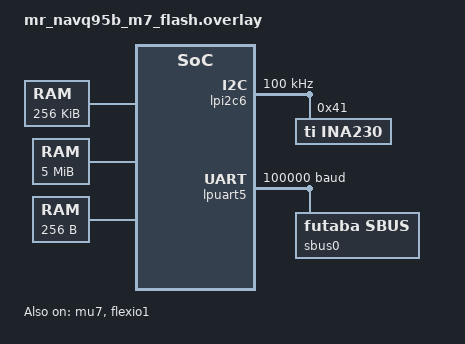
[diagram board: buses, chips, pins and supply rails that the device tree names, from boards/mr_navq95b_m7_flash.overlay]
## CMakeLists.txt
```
#-------------------------------------------------------------------------------
# Zephyr Cerebri Application
#
# Copyright (c) 2023 CogniPilot Foundation
# SPDX-License-Identifier: Apache-2.0

cmake_minimum_required(VERSION 3.13.1)

find_package(Zephyr REQUIRED HINTS $ENV{ZEPHYR_BASE})

project(rdd2 LANGUAGES C)

# Suppress strncpy warning from upstream Zephyr USB MSC code (usbd_msc_scsi.c)
# The strncpy usage is correct for fixed-size SCSI fields that don't need null termination
zephyr_compile_options(-Wno-stringop-truncation)

set(CYECCA_PYTHON ${CMAKE_CURRENT_SOURCE_DIR}/../../scripts/cyecca_python)

set(CYECCA_PATH $ENV{ZEPHYR_BASE}/../modules/lib/cyecca)

set(flags
  -std=c11
  -Wall
  -Wextra
  -Werror
  -Wstrict-prototypes
  -Waggregate-return
  -Wbad-function-cast
  -Wcast-align
  -Wcast-qual
  -Wfloat-equal
  -Wformat-security
  -Wlogical-op
  -Wmissing-declarations
  # ubxlib includes geographiclib which dir doesn't exist
  #-Wmissing-include-dirs
  -Wmissing-prototypes
  -Wnested-externs
  -Wpointer-arith
  -Wredundant-decls
  -Wsequence-point
  -Wshadow
  -Wstrict-prototypes
  -Wswitch
  -Wundef
  -Wunreachable-code
  -Wunused-but-set-parameter
  -Wwrite-strings
  )
string(JOIN " " flags ${flags})

set(SOURCE_FILES
  src/boot_banner.c
  src/input_mapping.c
  )

if (CONFIG_CEREBRI_RDD2_FSM)
  list(APPEND SOURCE_FILES src/fsm.c)
endif()

if (CONFIG_CEREBRI_RDD2_ESTIMATE)
  list(APPEND SOURCE_FILES src/estimate.c)
endif()

if (CONFIG_CEREBRI_RDD2_ALLOCATION)
  list(APPEND SOURCE_FILES src/allocation.c)
endif()

if (CONFIG_CEREBRI_RDD2_LIGHTING)
  list(APPEND SOURCE_FILES src/lighting.c)
endif()

if (CONFIG_CEREBRI_RDD2_COMMAND)
  list(APPEND SOURCE_FILES
    src/command.c
    src/mode_bezier.c
    src/mode_velocity.c
    src/mode_attitude.c
    src/mode_attitude_rate.c)
endif()

if (CONFIG_CEREBRI_RDD2_POSITION)
  list(APPEND SOURCE_FILES
    src/position.c)
elseif (CONFIG_CEREBRI_RDD2_LOGLINEAR_POSITION)
  list(APPEND SOURCE_FILES
    src/log_linear_position.c)
endif()

if (CONFIG_CEREBRI_RDD2_ANGULAR_VELOCITY)
  list(APPEND SOURCE_FILES
    src/angular_velocity.c)
endif()

if (CONFIG_CEREBRI_RDD2_ATTITUDE)
  list(APPEND SOURCE_FILES
    src/attitude.c)
elseif (CONFIG_CEREBRI_RDD2_LOGLINEAR_ATTITUDE)
  list(APPEND SOURCE_FILES
    src/log_linear_attitude.c)
endif()

set(CASADI_DEST_DIR ${CMAKE_BINARY_DIR}/app/rdd2/casadi)

set(CASADI_FILES
  ${CASADI_DEST_DIR}/rdd2.c
  ${CASADI_DEST_DIR}/rdd2_loglinear.c
  ${CASADI_DEST_DIR}/bezier.c
  )

if (CONFIG_CEREBRI_RDD2_CASADI)
  list(APPEND SOURCE_FILES ${CASADI_FILES})
endif()

add_custom_command(OUTPUT ${CASADI_DEST_DIR}/rdd2.c
  COMMAND ${CYECCA_PYTHON} ${CYECCA_PATH}/cyecca/models/rdd2.py ${CASADI_DEST_DIR}
  DEPENDS ${CYECCA_PATH}/cyecca/models/rdd2.py)

add_custom_command(OUTPUT ${CASADI_DEST_DIR}/rdd2_loglinear.c
  COMMAND ${CYECCA_PYTHON} ${CYECCA_PATH}/cyecca/models/rdd2_loglinear.py ${CASADI_DEST_DIR}
  DEPENDS ${CYECCA_PATH}/cyecca/models/rdd2_loglinear.py)

add_custom_command(OUTPUT ${CASADI_DEST_DIR}/bezier.c
  COMMAND ${CYECCA_PYTHON} ${CYECCA_PATH}/cyecca/models/bezier.py ${CASADI_DEST_DIR}
  DEPENDS ${CYECCA_PATH}/cyecca/models/bezier.py)

set_source_files_properties(
  ${SOURCE_FILES}
  PROPERTIES COMPILE_FLAGS
  "${flags}"
  )

set_source_files_properties(
  ${CASADI_FILES}
  PROPERTIES COMPILE_FLAGS
  "${flags}\
  -Wno-unused-parameter\
  -Wno-missing-prototypes\
  -Wno-missing-declarations\
  -Wno-float-equal")

target_sources(app PRIVATE ${SOURCE_FILES})

target_include_directories(app SYSTEM BEFORE PRIVATE
  ${ZEPHYR_BASE}/include
  ${CMAKE_BINARY_DIR}
  )

if(CONFIG_BOARD STREQUAL "vmu_rt1170")
  zephyr_linker_sources(ITCM_SECTION boards/vmu_rt1170_itcm_linker.ld)
  zephyr_code_relocate(LIBRARY nanopb LOCATION ITCM_TEXT)
endif()

if(CONFIG_BOARD STREQUAL "mr_vmu_tropic")
  zephyr_linker_sources(ITCM_SECTION boards/mr_vmu_tropic_itcm_linker.ld)
  zephyr_code_relocate(LIBRARY nanopb LOCATION ITCM_TEXT)
endif()

if(CONFIG_BOARD STREQUAL "mr_navq95a" OR CONFIG_BOARD STREQUAL "mr_navq95b")
  # Relocate code to ITCM
  zephyr_linker_sources(ITCM_SECTION boards/mr_navq95a_itcm_linker.ld)
  zephyr_code_relocate(LIBRARY nanopb LOCATION ITCM_TEXT)
  # Relocate log ring buffer to SDRAM
  zephyr_linker_sources(SECTIONS boards/navq95.ld)
  # Relocate data to OCRAM since zephyr doesn't have an auto spillover
  zephyr_code_relocate(FILES ${SOURCE_FILES} LOCATION OCRAM_DATA)
  zephyr_code_relocate(FILES ${SOURCE_FILES} LOCATION OCRAM_BSS)
  zephyr_code_relocate(FILES ${SOURCE_FILES} LOCATION OCRAM_NOINIT)
  zephyr_code_relocate(LIBRARY cerebri_synapse_topic LOCATION OCRAM_BSS)
  zephyr_code_relocate(LIBRARY cerebri_synapse_topic LOCATION OCRAM_NOINIT)
endif()

# vi: ts=2 sw=2 et
```

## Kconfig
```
# Copyright (c) 2023, CogniPilot Foundation
# SPDX-License-Identifier: Apache-2.0

mainmenu "CogniPilot - Cerebri - RDD2"
menu "Zephyr"
source "Kconfig.zephyr"
endmenu

menu "RDD2"
config CEREBRI_RDD2_ESTIMATE
  bool "enable estimate"
  depends on CEREBRI_RDD2_CASADI
  help
    Enable estimator

config CEREBRI_RDD2_FSM
  bool "enable finite state machine"
  help
    Enable fintie state machine

config CEREBRI_RDD2_LIGHTING
  bool "enable lighting"
  help
    Enable lighting

config CEREBRI_RDD2_COMMAND
  bool "enable command"
  depends on CEREBRI_RDD2_ALLOCATION
  help
    Enable joy

config CEREBRI_RDD2_ALLOCATION
  bool "enable mixing"
  help
    Enable mixing

config CEREBRI_RDD2_POSITION
  bool "enable position"
  depends on CEREBRI_RDD2_CASADI
  help
    Enable position

config CEREBRI_RDD2_ANGULAR_VELOCITY
  bool "enable velocity"
  depends on CEREBRI_RDD2_ALLOCATION
  depends on CEREBRI_RDD2_CASADI
  help
    Enable velocity

config CEREBRI_RDD2_ATTITUDE
  bool "enable attitude"
  depends on CEREBRI_RDD2_ANGULAR_VELOCITY
  depends on CEREBRI_RDD2_CASADI
  help
    Enable attitude

config CEREBRI_RDD2_CASADI
  bool "enable casadi code"
  help
    Enable Casadi generated code

config CEREBRI_RDD2_ESTIMATE_ODOMETRY_ETHERNET
  bool "fuse odometry from ethernet"
  depends on CEREBRI_RDD2_ESTIMATE
  help
    Enable odometry from ethernet

config CEREBRI_RDD2_BATTERY_NCELLS
  int "number of cells in battery"
  default 4
  help
    Number of cells in battery

config CEREBRI_RDD2_BATTERY_CELL_MIN_MILLIVOLT
  int "millivolts per cell before shutdown"
  default 3300
  help
    millivolts per cell before shutdown

config CEREBRI_RDD2_BATTERY_CELL_LOW_MILLIVOLT
  int "millivolts per cell before warning"
  default 3500
  help
    millivolts per cell before warning

config CEREBRI_RDD2_BATTERY_CELL_NOM_MILLIVOLT
  int "nominal millivolts per cell"
  default 3700
  help
    nominal millivolts per cell

config CEREBRI_RDD2_BATTERY_CELL_MAX_MILLIVOLT
  int "max millivolts per cell before warning"
  default 4300
  help
    max millivolts per cell before warning

config CEREBRI_RDD2_GAIN_HEADING
  int "heading gain"
  default 100
  help
    Steering = Heading error * GAIN_/ 1000

config CEREBRI_RDD2_GAIN_CROSS_TRACK
  int "cross track gain"
  default 100
  help
    Steering = Cross track error * GAIN / 1000

config CEREBRI_RDD2_GAIN_ALONG_TRACK
  int "along track gain"
  default 100
  help
    Steering = Along track error * GAIN / 1000

config CEREBRI_RDD2_MAX_VELOCITY_MM_S
  int "max velocity, mm/s"
  default 1000
  help
    Max velocity in mm/s

config CEREBRI_RDD2_MOTOR_L_MM
  int "moment arm for props"
  default 174
  help
    moment arm for props

config CEREBRI_RDD2_MOTOR_CM
  int "motor moment coefficient * 1e6"
  default 16000
  help
    moment arm for props

config CEREBRI_RDD2_MOTOR_CT
  int "motor thrust coefficient * 1e9"
  default 8549
  help
    moment thrust coefficient * 1e9

config CEREBRI_RDD2_POS_KP
  int "pos kp * 1e6"
  default 2000000
  help
    pos kp * 1e6

config CEREBRI_RDD2_VEL_KP
  int "vel kp * 1e6"
  default 2000000
  help
    vel kp * 1e6

config CEREBRI_RDD2_X_KI
  int "x ki * 1e6"
  default 100000
  help
    x ki * 1e6

config CEREBRI_RDD2_Y_KI
  int "y ki * 1e6"
  default 100000
  help
    y ki * 1e6

config CEREBRI_RDD2_Z_KI
  int "z ki * 1e6"
  default 100000
  help
    z ki * 1e6

config CEREBRI_RDD2_X_IMAX
  int "x imax * 1e6"
  default 250000
  help
    x ki * 1e6

config CEREBRI_RDD2_Y_IMAX
  int "y imax * 1e6"
  default 250000
  help
    y ki * 1e6

config CEREBRI_RDD2_Z_IMAX
  int "z imax * 1e6"
  default 250000
  help
    z imax * 1e6

config CEREBRI_RDD2_ROLL_KP
  int "roll kp * 1e6"
  default 2000000
  help
    roll kp * 1e6

config CEREBRI_RDD2_PITCH_KP
  int "pitch kp * 1e6"
  default 2000000
  help
    pitch kp * 1e6

config CEREBRI_RDD2_YAW_KP
  int "yaw kp * 1e6"
  default 1000000
  help
    yaw kp * 1e6

config CEREBRI_RDD2_ROLLRATE_KP
  int "rollrate kp * 1e6"
  default 300000
  help
    rollrate kp * 1e6

config CEREBRI_RDD2_PITCHRATE_KP
  int "pitchrate kp * 1e6"
  default 300000
  help
    pitchrate kp * 1e6

config CEREBRI_RDD2_YAWRATE_KP
  int "yawrate kp * 1e6"
  default 300000
  help
    yawrate kp * 1e6

config CEREBRI_RDD2_ROLLRATE_KI
  int "rollrate ki * 1e6"
  default 50000
  help
    rollrate ki * 1e6

config CEREBRI_RDD2_PITCHRATE_KI
  int "pitchrate ki * 1e6"
  default 50000
  help
    pitchrate ki * 1e6

config CEREBRI_RDD2_YAWRATE_KI
  int "yawrate ki * 1e6"
  default 50000
  help
    yawrate ki * 1e6

config CEREBRI_RDD2_ROLLRATE_KD
  int "rollrate kd * 1e6"
  default 0
  help
    rollrate kd * 1e6

config CEREBRI_RDD2_PITCHRATE_KD
  int "pitchrate kd * 1e6"
  default 0
  help
    pitchrate kd * 1e6

config CEREBRI_RDD2_YAWRATE_KD
  int "yawrate kd * 1e6"
  default 0
  help
    yawrate kd * 1e6

config CEREBRI_RDD2_ATTITUDE_RATE_FCUT
  int "fcut [hz] * 1e3"
  default 20000
  help
    attitude_rate cut frequency * 1e3

config CEREBRI_RDD2_ROLLRATE_IMAX
  int "rollrate imax * 1e3"
  default 20000
  help
    rollrate imax * 1e6

config CEREBRI_RDD2_PITCHRATE_IMAX
  int "pitchate imax * 1e3"
  default 20000
  help
    pitchrate imax * 1e6

config CEREBRI_RDD2_YAWRATE_IMAX
  int "yawrate imax * 1e6"
  default 20000
  help
    yawrate imax * 1e6

config CEREBRI_RDD2_THRUST_TRIM
  int "thrust_trim * 1e3 [N}"
  default 21952
  help
    thrust trim * 1e3 [N]

config CEREBRI_RDD2_THRUST_DELTA
  int "thrust delta* 1e3 [N}"
  default 19756
  help
    thrust delta imax * 1e3 [N}

config CEREBRI_RDD2_LOG_LINEAR_ATTITUDE
  bool "enable loglinear attitude control"
  help
    Enable loglinear atitude control

config CEREBRI_RDD2_LOG_LINEAR_POSITION
  bool "enable loglinear position control"
  help
    Enable loglinear atitude position

config CEREBRI_RDD2_ATTITUDE_EST_ACCEL_GAIN
  int "attitude rate accel gain"
  default 40
  help
    attitude rate accel gain

config CEREBRI_RDD2_ATTITUDE_EST_MAG_GAIN
  int "attitude rate mag gain"
  default 40
  help
    attitude rate mag gain


module = CEREBRI_RDD2
module-str = cerebri_rdd2
source "subsys/logging/Kconfig.template.log_config"
endmenu
```

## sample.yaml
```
sample:
  description: RDD2
  name: RDD2
common:
  build_only: true
tests:
  rdd2.posix:
    tags:
      - rdd2
    integration_platforms:
      - native_sim
  rdd2.vmu_rt1170/mimxrt1176/cm7:
    tags:
      - rdd2
    integration_platforms:
      - vmu_rt1170/mimxrt1176/cm7
  rdd2.mr_vmu_tropic/mimxrt1064:
    tags:
      - rdd2
    integration_platforms:
      - mr_vmu_tropic/mimxrt1064
  rdd2.mr_navq95a/mimx9596/m7/flash:
    tags:
      - rdd2
    integration_platforms:
      - mr_navq95a/mimx9596/m7/flash
  rdd2.mr_navq95b/mimx9596/m7/flash:
    tags:
      - rdd2
    integration_platforms:
      - mr_navq95b/mimx9596/m7/flash
```

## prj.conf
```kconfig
CONFIG_CEREBRI_APP_NAME="rdd2"

CONFIG_SYS_CLOCK_TICKS_PER_SEC=100000
CONFIG_TICKLESS_KERNEL=n

CONFIG_CEREBRI_DREAM_SIL=n

CONFIG_CEREBRI_RDD2_ESTIMATE=y
CONFIG_CEREBRI_RDD2_FSM=y
CONFIG_CEREBRI_RDD2_COMMAND=y
CONFIG_CEREBRI_RDD2_ALLOCATION=y
CONFIG_CEREBRI_RDD2_POSITION=y
CONFIG_CEREBRI_RDD2_ANGULAR_VELOCITY=y
CONFIG_CEREBRI_RDD2_ATTITUDE=y
CONFIG_CEREBRI_RDD2_LOG_LINEAR_POSITION=y
CONFIG_CEREBRI_RDD2_LOG_LINEAR_ATTITUDE=y
CONFIG_CEREBRI_RDD2_LIGHTING=n
CONFIG_CEREBRI_RDD2_CASADI=y
CONFIG_CEREBRI_ACTUATE_LED_ARRAY_COUNT=36

CONFIG_CEREBRI_ACTUATE_LED_ARRAY=y
CONFIG_CEREBRI_ACTUATE_SOUND=n

CONFIG_NET_BUF_RX_COUNT=24
CONFIG_NET_PKT_RX_COUNT=24

CONFIG_CEREBRI_SENSE_RC=y
CONFIG_INPUT_MODE_SYNCHRONOUS=y
CONFIG_CEREBRI_SENSE_POWER=y
CONFIG_CEREBRI_SENSE_SAFETY=n
CONFIG_ZROS_SENSE_IMU=n
CONFIG_ZROS_SENSE_MAG=n

CONFIG_CEREBRI_RDD2_ESTIMATE_ODOMETRY_ETHERNET=n
CONFIG_CEREBRI_SYNAPSE_ETH_RX=y
CONFIG_CEREBRI_SYNAPSE_ETH_TX=y
CONFIG_CEREBRI_SYNAPSE_LOG_SDCARD=y

CONFIG_CEREBRI_SYNAPSE_TOPIC=y
CONFIG_CEREBRI_CORE_COMMON=y
CONFIG_CEREBRI_CORE_COMMON_BOOT_BANNER=n
CONFIG_ZROS=y
CONFIG_SHELL_STACK_SIZE=8192
CONFIG_INIT_STACKS=y

CONFIG_LOG=y
CONFIG_LOG_CMDS=y
CONFIG_LOG_MODE_DEFERRED=y
CONFIG_CEREBRI_RDD2_LOG_LEVEL_DBG=n

CONFIG_SPI_RTIO=y
CONFIG_SPI_ASYNC=n
CONFIG_SPI_NXP_LPSPI_DMA=n
CONFIG_ICM4268X_DECODER=y
CONFIG_ICM4268X_STREAM=y

CONFIG_FILE_SYSTEM=y
CONFIG_FAT_FILESYSTEM_ELM=y
CONFIG_DISK_ACCESS=y
CONFIG_FS_FATFS_EXFAT=y
CONFIG_POSIX_FILE_SYSTEM=y
CONFIG_DISK_DRIVER_SDMMC=y
CONFIG_FS_FATFS_MOUNT_MKFS=y

CONFIG_CBPRINTF_FP_SUPPORT=y

# modules
CONFIG_SYNAPSE_PB=y
CONFIG_NANOPB=y

# General config
CONFIG_POSIX_API=y
CONFIG_NEWLIB_LIBC=y
CONFIG_MAIN_THREAD_PRIORITY=5
CONFIG_SYSTEM_WORKQUEUE_PRIORITY=-2

# Networking config
CONFIG_NET_SHELL=y
CONFIG_NETWORKING=y
CONFIG_NET_IPV4=y
CONFIG_NET_IPV6=n
CONFIG_NET_TCP=y
CONFIG_NET_SOCKETS=y

# Network address config
CONFIG_NET_CONFIG_SETTINGS=y
CONFIG_NET_CONFIG_INIT_TIMEOUT=0
CONFIG_NET_STATISTICS=y
CONFIG_NET_MGMT_EVENT_INFO=y
CONFIG_NET_MGMT_EVENT_MONITOR=y
CONFIG_NET_BUF_POOL_USAGE=y
CONFIG_NET_DEBUG_NET_PKT_ALLOC=y
CONFIG_NET_CONFIG_NEED_IPV4=y
CONFIG_NET_CONFIG_MY_IPV4_ADDR="192.0.2.1"
CONFIG_NET_CONFIG_PEER_IPV4_ADDR="192.0.2.2"

# STATS
CONFIG_THREAD_RUNTIME_STATS=y
CONFIG_SCHED_THREAD_USAGE=y
CONFIG_SCHED_THREAD_USAGE_ANALYSIS=y
CONFIG_SCHED_THREAD_USAGE_ALL=y
CONFIG_SCHED_THREAD_USAGE_AUTO_ENABLE=y
```

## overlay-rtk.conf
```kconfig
CONFIG_ZROS_SENSE_RTCM3_SUB=y
CONFIG_GNSS_U_BLOX_F9P_RTK=y
```

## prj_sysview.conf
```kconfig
CONFIG_TRACING=y
CONFIG_THREAD_NAME=y
CONFIG_THREAD_STACK_INFO=y
CONFIG_THREAD_MONITOR=y
CONFIG_SEGGER_SYSTEMVIEW=y
CONFIG_IDLE_STACK_SIZE=2048
CONFIG_SEGGER_SYSTEMVIEW_BOOT_ENABLE=n
CONFIG_SEGGER_SYSVIEW_POST_MORTEM_MODE=n
```

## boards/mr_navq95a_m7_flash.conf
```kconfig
CONFIG_ENTROPY_GENERATOR=y
CONFIG_TEST_RANDOM_GENERATOR=y
CONFIG_SPEED_OPTIMIZATIONS=n
CONFIG_SIZE_OPTIMIZATIONS=n
CONFIG_DEBUG_OPTIMIZATIONS=y
CONFIG_CODE_DATA_RELOCATION=y

CONFIG_TEST=y
CONFIG_UBSAN=n
CONFIG_ASSERT=y
CONFIG_ASSERT_LEVEL=2
CONFIG_ASSERT_VERBOSE=y
CONFIG_CODE_DATA_RELOCATION=y

CONFIG_CMSIS_DSP=y
CONFIG_CMSIS_DSP_FILTERING=y


CONFIG_SYSTEM_WORKQUEUE_STACK_SIZE=4096

CONFIG_STACK_CANARIES=y

CONFIG_ISR_STACK_SIZE=2048
CONFIG_SHELL_STACK_SIZE=4096

CONFIG_LOG_MODE_DEFERRED=y
CONFIG_LOG_MODE_IMMEDIATE=n

CONFIG_FPU=y

# gains
CONFIG_CEREBRI_RDD2_THRUST_TRIM=10976
CONFIG_CEREBRI_RDD2_THRUST_DELTA=10976

CONFIG_CEREBRI_RDD2_ROLL_KP=5000000
CONFIG_CEREBRI_RDD2_PITCH_KP=5000000
CONFIG_CEREBRI_RDD2_YAW_KP=2000000

CONFIG_CEREBRI_RDD2_ROLLRATE_KP=300000
CONFIG_CEREBRI_RDD2_PITCHRATE_KP=300000
CONFIG_CEREBRI_RDD2_YAWRATE_KP=50000

CONFIG_CEREBRI_RDD2_ROLLRATE_KI=50000
CONFIG_CEREBRI_RDD2_PITCHRATE_KI=50000
CONFIG_CEREBRI_RDD2_YAWRATE_KI=50000

CONFIG_CEREBRI_RDD2_ROLLRATE_IMAX=20000
CONFIG_CEREBRI_RDD2_PITCHRATE_IMAX=20000
CONFIG_CEREBRI_RDD2_YAWRATE_IMAX=20000

CONFIG_CEREBRI_RDD2_ROLLRATE_KD=10000
CONFIG_CEREBRI_RDD2_PITCHRATE_KD=10000
CONFIG_CEREBRI_RDD2_YAWRATE_KD=0
CONFIG_CEREBRI_RDD2_ATTITUDE_RATE_FCUT=10000

CONFIG_CEREBRI_RDD2_ATTITUDE_EST_ACCEL_GAIN=140
CONFIG_CEREBRI_RDD2_ATTITUDE_EST_MAG_GAIN=800

# RDD2 APPS
CONFIG_CEREBRI_RDD2_ALLOCATION=y
CONFIG_CEREBRI_RDD2_ANGULAR_VELOCITY=y
CONFIG_CEREBRI_RDD2_ATTITUDE=y
CONFIG_CEREBRI_RDD2_COMMAND=y
CONFIG_CEREBRI_RDD2_ESTIMATE=y
CONFIG_CEREBRI_RDD2_ESTIMATE_ODOMETRY_ETHERNET=n
CONFIG_CEREBRI_RDD2_FSM=y
CONFIG_CEREBRI_RDD2_LIGHTING=n
CONFIG_CEREBRI_RDD2_POSITION=y

# disabled for first live flight
CONFIG_CEREBRI_ACTUATE_PWM_SHELL=n
CONFIG_CEREBRI_ACTUATE_SOUND=n

# config
CONFIG_INPUT=y
CONFIG_INPUT_SBUS=y
CONFIG_INPUT_SBUS_THREAD_STACK_SIZE=1024
CONFIG_INPUT_EVENT_DUMP=n
CONFIG_INPUT_SHELL=n
CONFIG_INPUT_SBUS_REPORT_FILTER=0
CONFIG_INPUT_THREAD_STACK_SIZE=2048

CONFIG_DISK_ACCESS=n
CONFIG_FS_FATFS_EXFAT=n
CONFIG_DISK_DRIVER_SDMMC=n
CONFIG_FS_FATFS_MOUNT_MKFS=n
CONFIG_CEREBRI_SYNAPSE_LOG_SDCARD=y
CONFIG_RING_BUFFER_LARGE=y
CONFIG_ZROS_SENSE_IMU=y

CONFIG_CEREBRI_SENSE_RC=y
#CONFIG_ZROS_SENSE_MAG=y
CONFIG_CEREBRI_SENSE_SAFETY=n

# I3C tends to lock up the system, needs a driver fix
CONFIG_ZROS_SENSE_MAG=n
CONFIG_I3C=n
CONFIG_BMM350=n
CONFIG_BMP581=n

CONFIG_CEREBRI_SYNAPSE_ETH_RX=y
CONFIG_CEREBRI_SYNAPSE_ETH_TX=y
CONFIG_CEREBRI_ACTUATE_LED_ARRAY=n
CONFIG_CEREBRI_SENSE_POWER=y

CONFIG_PWM=y

CONFIG_LED_STRIP=n
CONFIG_APA102_STRIP=n

CONFIG_CAN=y
CONFIG_CAN_MAX_FILTER=5
CONFIG_CAN_SHELL=y

CONFIG_NET_DRIVERS=y

CONFIG_NET_SOCKETS_CAN=y
CONFIG_NET_DEFAULT_IF_CANBUS_RAW=y

CONFIG_CAN_LOG_LEVEL_DBG=n
CONFIG_CAN_FD_MODE=y
CONFIG_SHELL_ARGC_MAX=72
CONFIG_I2C=y
CONFIG_SENSOR=y
CONFIG_SENSOR_SHELL=y
CONFIG_HEAP_MEM_POOL_SIZE=16384

# Debugging
CONFIG_DEBUG_THREAD_INFO=y

# Logging
#CONFIG_LOG_BACKEND_NET=n
#CONFIG_LOG_BACKEND_NET_SERVER="192.0.2.2"

# RPMsg
CONFIG_IPM=y
CONFIG_IPM_MBOX=y
CONFIG_MBOX_NXP_IMX_MU=y
CONFIG_MBOX_INIT_PRIORITY=0
CONFIG_OPENAMP=y
CONFIG_OPENAMP_COPY_RSC_TABLE=y
CONFIG_OPENAMP_RSC_TABLE_NUM_RPMSG_BUFF=8
CONFIG_OPENAMP_RSC_TABLE=y
CONFIG_OPENAMP_MASTER=n
CONFIG_OPENAMP_WITH_DCACHE=y
CONFIG_CEREBRI_SYNAPSE_RPMSG=y

# TTY over RPMsg (uncomment block below to enable)
#CONFIG_SHELL_BACKEND_RPMSG=y
#CONFIG_SHELL_BACKEND_SERIAL=n
#CONFIG_ASSERT=n

# Disable fat and enable rpmsgfs
CONFIG_FILE_SYSTEM_RPMSGFS=y
CONFIG_FAT_FILESYSTEM_ELM=n
CONFIG_FILE_SYSTEM_SHELL=y

# Disable atomic 64 support otherwise open-amp cannot be linked
CONFIG_COMPILER_OPT="-DNO_ATOMIC_64_SUPPORT"
```

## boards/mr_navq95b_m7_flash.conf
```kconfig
CONFIG_ENTROPY_GENERATOR=y
CONFIG_TEST_RANDOM_GENERATOR=y
CONFIG_SPEED_OPTIMIZATIONS=n
CONFIG_SIZE_OPTIMIZATIONS=n
CONFIG_DEBUG_OPTIMIZATIONS=y
CONFIG_CODE_DATA_RELOCATION=y

CONFIG_TEST=y
CONFIG_UBSAN=n
CONFIG_ASSERT=y
CONFIG_ASSERT_LEVEL=2
CONFIG_ASSERT_VERBOSE=y
CONFIG_CODE_DATA_RELOCATION=y

CONFIG_CMSIS_DSP=y
CONFIG_CMSIS_DSP_FILTERING=y


CONFIG_SYSTEM_WORKQUEUE_STACK_SIZE=4096

CONFIG_STACK_CANARIES=y

CONFIG_ISR_STACK_SIZE=2048
CONFIG_SHELL_STACK_SIZE=4096

CONFIG_LOG_MODE_DEFERRED=y
CONFIG_LOG_MODE_IMMEDIATE=n

CONFIG_FPU=y

# gains
CONFIG_CEREBRI_RDD2_THRUST_TRIM=10976
CONFIG_CEREBRI_RDD2_THRUST_DELTA=10976

CONFIG_CEREBRI_RDD2_ROLL_KP=5000000
CONFIG_CEREBRI_RDD2_PITCH_KP=5000000
CONFIG_CEREBRI_RDD2_YAW_KP=2000000

CONFIG_CEREBRI_RDD2_ROLLRATE_KP=300000
CONFIG_CEREBRI_RDD2_PITCHRATE_KP=300000
CONFIG_CEREBRI_RDD2_YAWRATE_KP=50000

CONFIG_CEREBRI_RDD2_ROLLRATE_KI=50000
CONFIG_CEREBRI_RDD2_PITCHRATE_KI=50000
CONFIG_CEREBRI_RDD2_YAWRATE_KI=50000

CONFIG_CEREBRI_RDD2_ROLLRATE_IMAX=20000
CONFIG_CEREBRI_RDD2_PITCHRATE_IMAX=20000
CONFIG_CEREBRI_RDD2_YAWRATE_IMAX=20000

CONFIG_CEREBRI_RDD2_ROLLRATE_KD=10000
CONFIG_CEREBRI_RDD2_PITCHRATE_KD=10000
CONFIG_CEREBRI_RDD2_YAWRATE_KD=0
CONFIG_CEREBRI_RDD2_ATTITUDE_RATE_FCUT=10000

CONFIG_CEREBRI_RDD2_ATTITUDE_EST_ACCEL_GAIN=140
CONFIG_CEREBRI_RDD2_ATTITUDE_EST_MAG_GAIN=800

# RDD2 APPS
CONFIG_CEREBRI_RDD2_ALLOCATION=y
CONFIG_CEREBRI_RDD2_ANGULAR_VELOCITY=y
CONFIG_CEREBRI_RDD2_ATTITUDE=y
CONFIG_CEREBRI_RDD2_COMMAND=y
CONFIG_CEREBRI_RDD2_ESTIMATE=y
CONFIG_CEREBRI_RDD2_ESTIMATE_ODOMETRY_ETHERNET=n
CONFIG_CEREBRI_RDD2_FSM=y
CONFIG_CEREBRI_RDD2_LIGHTING=n
CONFIG_CEREBRI_RDD2_POSITION=y

# disabled for first live flight
CONFIG_CEREBRI_ACTUATE_PWM_SHELL=n
CONFIG_CEREBRI_ACTUATE_SOUND=n

# config
CONFIG_INPUT=y
CONFIG_INPUT_SBUS=y
CONFIG_INPUT_SBUS_THREAD_STACK_SIZE=1024
CONFIG_INPUT_EVENT_DUMP=n
CONFIG_INPUT_SHELL=n
CONFIG_INPUT_MODE_SYNCHRONOUS=n
CONFIG_INPUT_SBUS_REPORT_FILTER=0
CONFIG_INPUT_THREAD_STACK_SIZE=2048

CONFIG_DISK_ACCESS=n
CONFIG_FS_FATFS_EXFAT=n
CONFIG_DISK_DRIVER_SDMMC=n
CONFIG_FS_FATFS_MOUNT_MKFS=n
CONFIG_CEREBRI_SYNAPSE_LOG_SDCARD=y
CONFIG_RING_BUFFER_LARGE=y
CONFIG_ZROS_SENSE_STREAM=y
CONFIG_ZROS_SENSE_STREAM_IMU=y

CONFIG_ICM45686_STREAM=y

CONFIG_CEREBRI_SENSE_RC=y
CONFIG_CEREBRI_SENSE_SAFETY=n

CONFIG_ZROS_SENSE_MAG=y
CONFIG_I3C=y
CONFIG_BMM350=y
CONFIG_BMP581=y

CONFIG_CEREBRI_SYNAPSE_ETH_RX=y
CONFIG_CEREBRI_SYNAPSE_ETH_TX=y
CONFIG_CEREBRI_ACTUATE_LED_ARRAY=n
CONFIG_CEREBRI_SENSE_POWER=n # Needs pull-up

CONFIG_PWM=y

CONFIG_LED_STRIP=n
CONFIG_APA102_STRIP=n
CONFIG_ZROS_SENSE_MAG_COUNT=1

CONFIG_CAN=y
CONFIG_CAN_MAX_FILTER=5
CONFIG_CAN_SHELL=y

CONFIG_NET_DRIVERS=y

CONFIG_NET_SOCKETS_CAN=y
CONFIG_NET_DEFAULT_IF_CANBUS_RAW=y

CONFIG_CAN_LOG_LEVEL_DBG=n
CONFIG_CAN_FD_MODE=y
CONFIG_SHELL_ARGC_MAX=72
CONFIG_I2C=y
CONFIG_SENSOR=y
CONFIG_SENSOR_SHELL=y
CONFIG_HEAP_MEM_POOL_SIZE=16384

# Debugging
CONFIG_DEBUG_THREAD_INFO=y

# Logging
#CONFIG_LOG_BACKEND_NET=n
#CONFIG_LOG_BACKEND_NET_SERVER="192.0.2.2"

# RPMsg
CONFIG_IPM=y
CONFIG_IPM_MBOX=y
CONFIG_MBOX_NXP_IMX_MU=y
CONFIG_MBOX_INIT_PRIORITY=0
CONFIG_OPENAMP=y
CONFIG_OPENAMP_COPY_RSC_TABLE=y
CONFIG_OPENAMP_RSC_TABLE_NUM_RPMSG_BUFF=8
CONFIG_OPENAMP_RSC_TABLE=y
CONFIG_OPENAMP_MASTER=n
CONFIG_OPENAMP_WITH_DCACHE=y
CONFIG_CEREBRI_SYNAPSE_RPMSG=y

# TTY over RPMsg (uncomment block below to enable)
#CONFIG_SHELL_BACKEND_RPMSG=y
#CONFIG_SHELL_BACKEND_SERIAL=n
#CONFIG_ASSERT=n

# Disable fat and enable rpmsgfs
CONFIG_FILE_SYSTEM_RPMSGFS=y
CONFIG_FAT_FILESYSTEM_ELM=n
CONFIG_FILE_SYSTEM_SHELL=y

# Disable atomic 64 support otherwise open-amp cannot be linked
CONFIG_COMPILER_OPT="-DNO_ATOMIC_64_SUPPORT"
```

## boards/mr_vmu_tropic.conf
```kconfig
#CONFIG_SPEED_OPTIMIZATIONS=y
CONFIG_SIZE_OPTIMIZATIONS=y
CONFIG_CODE_DATA_RELOCATION=y

CONFIG_TEST=y
CONFIG_UBSAN=n
CONFIG_ASSERT=n

CONFIG_CMSIS_DSP=y
CONFIG_CMSIS_DSP_FILTERING=y


CONFIG_SYSTEM_WORKQUEUE_STACK_SIZE=4096

CONFIG_STACK_CANARIES=y

CONFIG_ISR_STACK_SIZE=8192

CONFIG_LOG_MODE_DEFERRED=y
CONFIG_LOG_MODE_IMMEDIATE=n

CONFIG_FPU=y

# gains
CONFIG_CEREBRI_RDD2_THRUST_TRIM=10976
CONFIG_CEREBRI_RDD2_THRUST_DELTA=10976

CONFIG_CEREBRI_RDD2_ROLL_KP=2000000
CONFIG_CEREBRI_RDD2_PITCH_KP=2000000
CONFIG_CEREBRI_RDD2_YAW_KP=1000000

# Rate PID gains are now hardcoded in angular_velocity.c (cerebri2 style)
# Roll/Pitch: kp=0.12, ki=0.35, kd=0.0015
# Yaw: kp=0.20, ki=0.20, kd=0.0

CONFIG_CEREBRI_RDD2_ATTITUDE_EST_ACCEL_GAIN=140
CONFIG_CEREBRI_RDD2_ATTITUDE_EST_MAG_GAIN=800

# RDD2 APPS
CONFIG_CEREBRI_RDD2_ALLOCATION=y
CONFIG_CEREBRI_RDD2_ANGULAR_VELOCITY=y
CONFIG_CEREBRI_RDD2_ATTITUDE=y
CONFIG_CEREBRI_RDD2_COMMAND=y
CONFIG_CEREBRI_RDD2_ESTIMATE=y
CONFIG_CEREBRI_RDD2_ESTIMATE_ODOMETRY_ETHERNET=n
CONFIG_CEREBRI_RDD2_FSM=y
CONFIG_CEREBRI_RDD2_LIGHTING=n
CONFIG_CEREBRI_RDD2_POSITION=y

# disabled for first live flight
CONFIG_CEREBRI_ACTUATE_PWM_SHELL=n
CONFIG_CEREBRI_ACTUATE_SOUND=y

# config
CONFIG_INPUT=y
CONFIG_INPUT_SBUS_THREAD_STACK_SIZE=8192
CONFIG_INPUT_EVENT_DUMP=n
CONFIG_INPUT_SHELL=n
CONFIG_INPUT_SBUS_REPORT_FILTER=0

CONFIG_CEREBRI_SYNAPSE_LOG_SDCARD=y
CONFIG_ZROS_SENSE_STREAM=y
#CONFIG_ZROS_SENSE_STREAM_IMU=y
#CONFIG_ICM45686_STREAM=y
#CONFIG_ZROS_SENSE_IMU=y

CONFIG_CEREBRI_SENSE_RC=y
CONFIG_ZROS_SENSE_MAG=y
CONFIG_CEREBRI_SENSE_SAFETY=y
CONFIG_ZROS_SENSE_GNSS=y

CONFIG_CEREBRI_SYNAPSE_ETH_RX=y
CONFIG_CEREBRI_SYNAPSE_ETH_TX=y
CONFIG_CEREBRI_ACTUATE_LED_ARRAY=n
CONFIG_CEREBRI_SENSE_POWER=y

CONFIG_PWM=y

CONFIG_ZROS_SENSE_MAG_COUNT=1

CONFIG_CAN=y
CONFIG_CAN_MAX_FILTER=5
CONFIG_CAN_SHELL=y

CONFIG_NET_DRIVERS=y
CONFIG_NET_CANBUS=y

CONFIG_NET_SOCKETS_CAN=y
CONFIG_NET_DEFAULT_IF_CANBUS_RAW=y

CONFIG_CAN_LOG_LEVEL_DBG=n
CONFIG_CAN_FD_MODE=y
CONFIG_SHELL_ARGC_MAX=72
CONFIG_I2C=y
CONFIG_SENSOR=y
CONFIG_SENSOR_SHELL=y
CONFIG_HEAP_MEM_POOL_SIZE=16384

# Debugging
CONFIG_DEBUG_THREAD_INFO=y

# Logging
#CONFIG_LOG_BACKEND_NET=n
#CONFIG_LOG_BACKEND_NET_SERVER="192.0.2.2"
```

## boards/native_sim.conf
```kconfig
# gains
CONFIG_CEREBRI_RDD2_THRUST_TRIM=21952
CONFIG_CEREBRI_RDD2_THRUST_DELTA=19756

CONFIG_CEREBRI_RDD2_ESTIMATE_ODOMETRY_ETHERNET=n

CONFIG_CEREBRI_RDD2_ROLL_KP=5000000
CONFIG_CEREBRI_RDD2_PITCH_KP=5000000
CONFIG_CEREBRI_RDD2_YAW_KP=2000000

CONFIG_CEREBRI_RDD2_ROLLRATE_KP=300000
CONFIG_CEREBRI_RDD2_PITCHRATE_KP=300000
CONFIG_CEREBRI_RDD2_YAWRATE_KP=50000

CONFIG_CEREBRI_RDD2_ROLLRATE_KI=50000
CONFIG_CEREBRI_RDD2_PITCHRATE_KI=50000
CONFIG_CEREBRI_RDD2_YAWRATE_KI=50000

CONFIG_CEREBRI_RDD2_ROLLRATE_IMAX=20000
CONFIG_CEREBRI_RDD2_PITCHRATE_IMAX=20000
CONFIG_CEREBRI_RDD2_YAWRATE_IMAX=20000

CONFIG_CEREBRI_RDD2_ROLLRATE_KD=10000
CONFIG_CEREBRI_RDD2_PITCHRATE_KD=10000
CONFIG_CEREBRI_RDD2_YAWRATE_KD=0
CONFIG_CEREBRI_RDD2_ATTITUDE_RATE_FCUT=10000

CONFIG_CEREBRI_RDD2_ATTITUDE_EST_ACCEL_GAIN=150
CONFIG_CEREBRI_RDD2_ATTITUDE_EST_MAG_GAIN=150

# config
CONFIG_ETH_NATIVE_POSIX=y
CONFIG_TEST_RANDOM_GENERATOR=y
CONFIG_SYS_CLOCK_TICKS_PER_SEC=500
CONFIG_NATIVE_POSIX_SLOWDOWN_TO_REAL_TIME=n

CONFIG_NO_OPTIMIZATIONS=y
CONFIG_UART_NATIVE_PTY=y

CONFIG_REBOOT=n
CONFIG_LOG_BACKEND_NATIVE_POSIX=y
CONFIG_LOG_MODE_DEFERRED=n
CONFIG_LOG_MODE_IMMEDIATE=y

CONFIG_UART_NATIVE_PTY_0_ON_OWN_PTY=y
CONFIG_UART_NATIVE_PTY_0_ON_STDINOUT=n
CONFIG_UART_NATIVE_PTY_AUTOATTACH_DEFAULT_CMD="xterm -fa Monospcae -fs 12 -fg grey -bg black -T cerebri-shell -e screen %s &"

CONFIG_CEREBRI_BOOT_BANNER=n
CONFIG_CEREBRI_DREAM_SIL=y

CONFIG_TEST=y
CONFIG_ASAN=y
CONFIG_UBSAN=n
CONFIG_ASSERT=y
CONFIG_ASSERT_LEVEL=2
CONFIG_ASSERT_VERBOSE=y

CONFIG_CEREBRI_ACTUATE_LED_ARRAY=n
CONFIG_CEREBRI_ACTUATE_SOUND=n
CONFIG_CEREBRI_ACTUATE_PWM=n
CONFIG_CEREBRI_SENSE_POWER=n
CONFIG_CEREBRI_SENSE_RC=n
CONFIG_ZROS_SENSE_IMU=n
CONFIG_ZROS_SENSE_BARO=n
CONFIG_ZROS_SENSE_MAG=n
CONFIG_ZROS_SENSE_GNSS=n
CONFIG_CEREBRI_SENSE_SAFETY=n
CONFIG_CEREBRI_SENSE_WHEEL_ODOMETRY=n

CONFIG_DISK_ACCESS=n
CONFIG_FS_FATFS_EXFAT=n
CONFIG_DISK_DRIVER_SDMMC=n
CONFIG_FS_FATFS_MOUNT_MKFS=n
CONFIG_CEREBRI_SYNAPSE_LOG_SDCARD=n

CONFIG_NEWLIB_LIBC=n
CONFIG_EXTERNAL_LIBC=y
CONFIG_POSIX_API=n
```

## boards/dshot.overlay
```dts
/ {
	/delete-node/ pwm_actuators;

	dshot_actuators: dshot_actuators {
		compatible = "cerebri,dshot-actuators";
		aux0 {
			input-type = "velocity";
			input-index = <0>;
			center = <200>;
			scale = <1500>;
			scale-div = <1000>;
		};
		aux1 {
			input-type = "velocity";
			input-index = <1>;
			center = <200>;
			scale = <1500>;
			scale-div = <1000>;
		};
		aux2 {
			input-type = "velocity";
			input-index = <2>;
			center = <200>;
			scale = <1500>;
			scale-div = <1000>;
		};
		aux3 {
			input-type = "velocity";
			input-index = <3>;
			center = <200>;
			scale = <1500>;
			scale-div = <1000>;
		};
	};
};

&flexpwm1_pwm0 {
	status = "disabled";
};

&flexpwm1_pwm1 {
	status = "disabled";
};

&flexpwm1_pwm2	{
	status = "disabled";
};

&flexpwm2_pwm0	{
	status = "disabled";
};

&flexpwm2_pwm1	{
	status = "disabled";
};

&flexpwm2_pwm2	{
	status = "disabled";
};

&flexpwm2_pwm3	{
	status = "disabled";
};

&flexpwm3_pwm0	{
	status = "disabled";
};

&dshot {
	status = "okay";
};
```

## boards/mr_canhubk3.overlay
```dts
/* SPDX-License-Identifier: Apache-2.0 */
/* Copyright 2023 CogniPilot Foundation */
#include <zephyr/dt-bindings/sensor/ina230.h>

/ {
	pwm_shell: pwm_shell {
		compatible = "pwm-leds";
		aux0: aux0 {
			pwms = <&emios0_pwm 0 PWM_HZ(50) PWM_POLARITY_NORMAL>;
		};
		aux1: aux1 {
			pwms = <&emios0_pwm 1 PWM_HZ(20000) PWM_POLARITY_NORMAL>;
		};
		aux2: aux2 {
			pwms = <&emios0_pwm 2 PWM_HZ(20000) PWM_POLARITY_NORMAL>;
		};
		aux3: aux3 {
			pwms = <&emios0_pwm 3 PWM_HZ(50) PWM_POLARITY_NORMAL>;
		};
		aux4: aux4 {
			pwms = <&emios0_pwm 4 PWM_HZ(50) PWM_POLARITY_NORMAL>;
		};
		aux5: aux5 {
			pwms = <&emios0_pwm 5 PWM_HZ(50) PWM_POLARITY_NORMAL>;
		};
	};

	chosen {
		zephyr,canbus = &flexcan3;
	};

	aliases {
		can0 = &flexcan0;
		can1 = &flexcan1;
		can2 = &flexcan2;
		can3 = &flexcan3;
		can4 = &flexcan4;
		can5 = &flexcan5;
		/* power sensors */
		power0 = &ina230;
		/* safety button */
		safety-button = &arming_button_mr_canhubk3_adap;
		/* wheel odometry */
		wheel-odometry0 = &qdec0;
	};
};

&emios0_pwm {
	pwm_0 {
	};
	pwm_1 {
		prescaler = <1>;
	};
	pwm_2 {
		prescaler = <1>;
		duty-cycle = <0>;
	};
	pwm_3 {
		prescaler = <16>;
	};
	pwm_4 {
		prescaler = <16>;
	};
	pwm_5 {
		prescaler = <16>;
	};
};



&flexcan0 {
	status = "okay";
	bus-speed = <1000000>;
	bus-speed-data = <4000000>;
};

&flexcan1 {
	status = "okay";
	bus-speed = <1000000>;
	bus-speed-data = <4000000>;
};

&flexcan2 {
	status = "okay";
	bus-speed = <1000000>;
	bus-speed-data = <4000000>;
};

&flexcan3 {
	status = "okay";
	bus-speed = <1000000>;
	bus-speed-data = <4000000>;
};

&flexcan4 {
	status = "okay";
	bus-speed = <1000000>;
	bus-speed-data = <4000000>;
};

&flexcan5 {
	status = "okay";
	bus-speed = <1000000>;
	bus-speed-data = <4000000>;
};

&lpspi2 {
	status = "okay";
	apa102: apa102@0 {
	compatible = "apa,apa102";
		status = "okay";
		reg = <0>;
		spi-max-frequency = <100000>;
	};
};

&lpi2c1 {
	status = "okay";
	pinctrl-0 = <&lpi2c1_default>;
	pinctrl-names = "default";
	clock-frequency = <I2C_BITRATE_STANDARD>;

	ina230: ina230@41 {
		compatible = "ti,ina230";
		reg = <0x41>;
		current-lsb-microamps = <5000>;
		rshunt-micro-ohms = <500>;
	};
};

/* GNSS 1 */
uart0: &lpuart7 {
		status = "okay";
		current-speed = <38400>;
};
```

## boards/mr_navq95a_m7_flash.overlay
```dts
/* SPDX-License-Identifier: Apache-2.0 */
/* Copyright 2025 CogniPilot Foundation */
#include <freq.h>
#include <zephyr/dt-bindings/input/input-event-codes.h>
#include <zephyr/dt-bindings/led/led.h>
#include <zephyr/dt-bindings/sensor/ina230.h>
#include <zephyr/dt-bindings/memory-attr/memory-attr-arm.h>

/ {
	dshot_actuators: dshot_actuators {
		compatible = "cerebri,dshot-actuators";
		aux0 {
			input-type = "velocity";
			input-index = <0>;
			center = <200>;
			scale = <1500>;
			scale-div = <1000>;
		};
		aux1 {
			input-type = "velocity";
			input-index = <1>;
			center = <200>;
			scale = <1500>;
			scale-div = <1000>;
		};
		aux2 {
			input-type = "velocity";
			input-index = <2>;
			center = <200>;
			scale = <1500>;
			scale-div = <1000>;
		};
		aux3 {
			input-type = "velocity";
			input-index = <3>;
			center = <200>;
			scale = <1500>;
			scale-div = <1000>;
		};
	};

	chosen {
		/* zephyr,canbus = &flexcan5; */ 

		zephyr,ipc_shm = &shmem;
		zephyr,ipc_rsc_table = &rsc_table;
		zephyr,ipc = &mailbox0;
	};

	ocram: memory@20480000 {
		compatible = "zephyr,memory-region", "mmio-sram";
		device_type = "memory";
		reg = <0x20480000 DT_SIZE_K(256)>;
		zephyr,memory-region = "OCRAM";
		zephyr,memory-attr = <( DT_MEM_ARM(ATTR_MPU_RAM) )>;
	};

	ddr: ddr@90000000 {
		compatible = "zephyr,memory-region", "mmio-sram";
		device_type = "memory";
		reg = <0x90000000 DT_SIZE_M(4)>;
		zephyr,memory-region = "DDR";
		zephyr,memory-attr = <( DT_MEM_ARM(ATTR_MPU_RAM) )>;
	};

	shmem: memory@88000000 {
		compatible = "mmio-sram";
		reg = <0x88000000 0x500000>;
	};

	rsc_table: memory@88220000 {
		compatible = "mmio-sram";
		reg = <0x88220000 0x100>;
	};

	mailbox0: mailbox {
		compatible = "zephyr,mbox-ipm";
		mboxes = <&mu7 1>, <&mu7 1>;
		mbox-names = "tx", "rx";
		status = "okay";
	};

	aliases {
		accel0 = &bmi08x_accel;
		gyro0 = &bmi08x_gyro;
		mag0 = &bmm350;
		power0 = &ina230;
		rc = &sbus0;
		/* can0 = &flexcan5; */
	};
};

&tpm3 {
	status = "disabled";
};

&tpm4 {
	status = "disabled";
};

&tpm5 {
	status = "disabled";
};

&lpi2c8 {
	clock-frequency = <I2C_BITRATE_STANDARD>;

	ina230: ina230@40 {
		compatible = "ti,ina230";
		reg = <0x40>;
		current-lsb-microamps = <10000>;
		rshunt-micro-ohms = <2000>;
	};
};

&lpuart7 {
	status = "okay";
	current-speed = <100000>;
	single-wire;
	rx-invert;

	sbus0: sbus {
		compatible = "futaba,sbus";
		chan_1 {
			channel = <1>;
			type = <INPUT_EV_ABS>;
			zephyr,code = <1>;
		};
		chan_2 {
			channel = <2>;
			type = <INPUT_EV_ABS>;
			zephyr,code = <2>;
		};
		chan_3 {
			channel = <3>;
			type = <INPUT_EV_ABS>;
			zephyr,code = <3>;
		};
		chan_4 {
			channel = <4>;
			type = <INPUT_EV_ABS>;
			zephyr,code = <4>;
		};
		chan_5 {
			channel = <5>;
			type = <INPUT_EV_ABS>;
			zephyr,code = <5>;
		};
		chan_6 {
			channel = <6>;
			type = <INPUT_EV_ABS>;
			zephyr,code = <6>;
		};
		chan_7 {
			channel = <7>;
			type = <INPUT_EV_ABS>;
			zephyr,code = <7>;
		};
		chan_8 {
			channel = <8>;
			type = <INPUT_EV_ABS>;
			zephyr,code = <8>;
		};
		chan_9 {
			channel = <9>;
			type = <INPUT_EV_ABS>;
			zephyr,code = <9>;
		};
		chan_10 {
			channel = <10>;
			type = <INPUT_EV_ABS>;
			zephyr,code = <10>;
		};
		chan_11 {
			channel = <11>;
			type = <INPUT_EV_ABS>;
			zephyr,code = <11>;
		};
		chan_12 {
			channel = <12>;
			type = <INPUT_EV_ABS>;
			zephyr,code = <12>;
		};
		chan_13 {
			channel = <13>;
			type = <INPUT_EV_ABS>;
			zephyr,code = <13>;
		};
		chan_14 {
			channel = <14>;
			type = <INPUT_EV_ABS>;
			zephyr,code = <14>;
		};
		chan_15 {
			channel = <15>;
			type = <INPUT_EV_ABS>;
			zephyr,code = <15>;
		};
		chan_16 {
			channel = <16>;
			type = <INPUT_EV_ABS>;
			zephyr,code = <16>;
		};
	};
};

&mu7 {
	status = "okay";
};

/* DSHOT */

&pinctrl {

	pinmux_dshot_j13: pinmux_dshot_j13 {
		group0 {
			pinmux = <&iomuxc_gpio_io06_flexio_flexio_bit_flexio1_flexio_bit6>,
				<&iomuxc_gpio_io05_flexio_flexio_bit_flexio1_flexio_bit5>,
				<&iomuxc_gpio_io20_flexio_flexio_bit_flexio1_flexio_bit20>,
				<&iomuxc_gpio_io21_flexio_flexio_bit_flexio1_flexio_bit21>,
				<&iomuxc_gpio_io18_flexio_flexio_bit_flexio1_flexio_bit18>,
				<&iomuxc_gpio_io26_flexio_flexio_bit_flexio1_flexio_bit26>;
			slew-rate = "slightly_fast";
			drive-strength = "x4";
			bias-pull-up;
			input-enable;
		};
	};
};

&flexio1 {
	status = "okay";

	dshot: dshot {
		compatible = "nxp,flexio-dshot";
		pinctrl-0 = <&pinmux_dshot_j13>;
		pinctrl-names = "default";
		status = "okay";
		speed = <600>;

		ch1 {
			pin-id = <20>;
		};

		ch2 {
			pin-id = <5>;
		};

		ch3 {
			pin-id = <21>;
		};

		ch4 {
			pin-id = <6>;
		};

	};

};
```

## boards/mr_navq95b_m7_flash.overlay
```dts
/* SPDX-License-Identifier: Apache-2.0 */
/* Copyright 2025 CogniPilot Foundation */
#include <freq.h>
#include <zephyr/dt-bindings/input/input-event-codes.h>
#include <zephyr/dt-bindings/led/led.h>
#include <zephyr/dt-bindings/sensor/ina230.h>
#include <zephyr/dt-bindings/sensor/icm45686.h>
#include <zephyr/dt-bindings/sensor/sensor_axis_align.h>
#include <zephyr/dt-bindings/memory-attr/memory-attr-arm.h>

/ {
	dshot_actuators: dshot_actuators {
		compatible = "cerebri,dshot-actuators";
		aux0 {
			input-type = "velocity";
			input-index = <3>;
			center = <200>;
			scale = <1500>;
			scale-div = <1000>;
		};
		aux1 {
			input-type = "velocity";
			input-index = <2>;
			center = <200>;
			scale = <1500>;
			scale-div = <1000>;
		};
		aux2 {
			input-type = "velocity";
			input-index = <1>;
			center = <200>;
			scale = <1500>;
			scale-div = <1000>;
		};
		aux3 {
			input-type = "velocity";
			input-index = <0>;
			center = <200>;
			scale = <1500>;
			scale-div = <1000>;
		};
	};

	chosen {
		/* zephyr,canbus = &flexcan5; */ 

		zephyr,ipc_shm = &shmem;
		zephyr,ipc_rsc_table = &rsc_table;
		zephyr,ipc = &mailbox0;
	};

	ocram: memory@20480000 {
		compatible = "zephyr,memory-region", "mmio-sram";
		device_type = "memory";
		reg = <0x20480000 DT_SIZE_K(256)>;
		zephyr,memory-region = "OCRAM";
		zephyr,memory-attr = <( DT_MEM_ARM(ATTR_MPU_RAM) )>;
	};

	ddr: ddr@90000000 {
		compatible = "zephyr,memory-region", "mmio-sram";
		device_type = "memory";
		reg = <0x90000000 DT_SIZE_M(4)>;
		zephyr,memory-region = "DDR";
		zephyr,memory-attr = <( DT_MEM_ARM(ATTR_MPU_RAM) )>;
	};

	shmem: memory@88000000 {
		compatible = "mmio-sram";
		reg = <0x88000000 0x500000>;
	};

	rsc_table: memory@88220000 {
		compatible = "mmio-sram";
		reg = <0x88220000 0x100>;
	};

	mailbox0: mailbox {
		compatible = "zephyr,mbox-ipm";
		mboxes = <&mu7 1>, <&mu7 1>;
		mbox-names = "tx", "rx";
		status = "okay";
	};

	aliases {
		imu-stream-0 = &icm45686;
		mag0 = &bmm350;
		power0 = &ina230;
		rc = &sbus0;
		/* can0 = &flexcan5; */
	};
};

/* Some attempt at rotation */

&icm45686 {
	axis-align-x = <SENSOR_AXIS_ALIGN_DT_X>;
	axis-align-y = <SENSOR_AXIS_ALIGN_DT_Y>;
	axis-align-z = <SENSOR_AXIS_ALIGN_DT_Z>;
	axis-align-y-sign = <SENSOR_AXIS_ALIGN_DT_NEG>;
	axis-align-z-sign = <SENSOR_AXIS_ALIGN_DT_NEG>;
};

&bmm350 {
	axis-align-x = <SENSOR_AXIS_ALIGN_DT_Y>;
	axis-align-y = <SENSOR_AXIS_ALIGN_DT_X>;
	axis-align-z = <SENSOR_AXIS_ALIGN_DT_Z>;
	axis-align-x-sign = <SENSOR_AXIS_ALIGN_DT_NEG>;
	axis-align-z-sign = <SENSOR_AXIS_ALIGN_DT_NEG>;
};

/* BMI088 not supported yet with streaming
&bmi08x_accel {
	axis-align-x = <SENSOR_AXIS_ALIGN_DT_Y>;
	axis-align-y = <SENSOR_AXIS_ALIGN_DT_X>;
	axis-align-z = <SENSOR_AXIS_ALIGN_DT_Z>;
	axis-align-x-sign = <SENSOR_AXIS_ALIGN_DT_NEG>;
};

&bmi08x_gyro {
	axis-align-x = <SENSOR_AXIS_ALIGN_DT_Y>;
	axis-align-y = <SENSOR_AXIS_ALIGN_DT_X>;
	axis-align-z = <SENSOR_AXIS_ALIGN_DT_Z>;
	axis-align-x-sign = <SENSOR_AXIS_ALIGN_DT_NEG>;
};*/

&tpm5 {
	prescaler = <4>;
};

&lpi2c6 {
	clock-frequency = <I2C_BITRATE_STANDARD>;

	ina230: ina230@41 {
		compatible = "ti,ina230";
		reg = <0x41>;
		current-lsb-microamps = <10000>;
		rshunt-micro-ohms = <2000>;
	};
};

&lpuart5 {
	status = "okay";
	current-speed = <100000>;
	rx-invert;

	sbus0: sbus {
		compatible = "futaba,sbus";
		chan_1 {
			channel = <1>;
			type = <INPUT_EV_ABS>;
			zephyr,code = <1>;
		};
		chan_2 {
			channel = <2>;
			type = <INPUT_EV_ABS>;
			zephyr,code = <2>;
		};
		chan_3 {
			channel = <3>;
			type = <INPUT_EV_ABS>;
			zephyr,code = <3>;
		};
		chan_4 {
			channel = <4>;
			type = <INPUT_EV_ABS>;
			zephyr,code = <4>;
		};
		chan_5 {
			channel = <5>;
			type = <INPUT_EV_ABS>;
			zephyr,code = <5>;
		};
		chan_6 {
			channel = <6>;
			type = <INPUT_EV_ABS>;
			zephyr,code = <6>;
		};
		chan_7 {
			channel = <7>;
			type = <INPUT_EV_ABS>;
			zephyr,code = <7>;
		};
		chan_8 {
			channel = <8>;
			type = <INPUT_EV_ABS>;
			zephyr,code = <8>;
		};
		chan_9 {
			channel = <9>;
			type = <INPUT_EV_ABS>;
			zephyr,code = <9>;
		};
		chan_10 {
			channel = <10>;
			type = <INPUT_EV_ABS>;
			zephyr,code = <10>;
		};
		chan_11 {
			channel = <11>;
			type = <INPUT_EV_ABS>;
			zephyr,code = <11>;
		};
		chan_12 {
			channel = <12>;
			type = <INPUT_EV_ABS>;
			zephyr,code = <12>;
		};
		chan_13 {
			channel = <13>;
			type = <INPUT_EV_ABS>;
			zephyr,code = <13>;
		};
		chan_14 {
			channel = <14>;
			type = <INPUT_EV_ABS>;
			zephyr,code = <14>;
		};
		chan_15 {
			channel = <15>;
			type = <INPUT_EV_ABS>;
			zephyr,code = <15>;
		};
		chan_16 {
			channel = <16>;
			type = <INPUT_EV_ABS>;
			zephyr,code = <16>;
		};
	};
};

&mu7 {
	status = "okay";
};

/* DSHOT */

&pinctrl {

	pinmux_dshot_j12: pinmux_dshot_j12 {
		group0 {
			pinmux = <&iomuxc_gpio_io04_flexio_flexio_bit_flexio1_flexio_bit4>,
				<&iomuxc_gpio_io20_flexio_flexio_bit_flexio1_flexio_bit20>,
				<&iomuxc_gpio_io24_flexio_flexio_bit_flexio1_flexio_bit24>,
				<&iomuxc_gpio_io05_flexio_flexio_bit_flexio1_flexio_bit5>,
				<&iomuxc_gpio_io21_flexio_flexio_bit_flexio1_flexio_bit21>,
				<&iomuxc_gpio_io06_flexio_flexio_bit_flexio1_flexio_bit6>;
			slew-rate = "slightly_fast";
			drive-strength = "x4";
			bias-pull-up;
			input-enable;
		};
	};

	lpuart7_sbus: lpuart7_sbus {
		group0 {
			pinmux = <&iomuxc_gpio_io08_lpuart_tx_lpuart7_tx>;
			bias-pull-up;
			slew-rate = "slightly_fast";
			drive-strength = "x4";
		};
	};
};

&flexio1 {
	status = "okay";

	dshot: dshot {
		compatible = "nxp,flexio-dshot";
		pinctrl-0 = <&pinmux_dshot_j12>;
		pinctrl-names = "default";
		status = "okay";
		speed = <300>;

		ch1 {
			pin-id = <4>;
		};

		ch2 {
			pin-id = <20>;
		};

		ch3 {
			pin-id = <24>;
		};

		ch4 {
			pin-id = <5>;
		};

	};

};
```

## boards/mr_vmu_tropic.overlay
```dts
/* SPDX-License-Identifier: Apache-2.0 */
/* Copyright 2024 CogniPilot Foundation */
#include <zephyr/dt-bindings/sensor/ina230.h>
#include <zephyr/dt-bindings/input/input-event-codes.h>

/ {
	dshot_actuators: dshot_actuators {
		compatible = "cerebri,dshot-actuators";
		aux0 {
			input-type = "velocity";
			input-index = <0>;
			center = <200>;
			scale = <1500>;
			scale-div = <1000>;
		};
		aux1 {
			input-type = "velocity";
			input-index = <1>;
			center = <200>;
			scale = <1500>;
			scale-div = <1000>;
		};
		aux2 {
			input-type = "velocity";
			input-index = <2>;
			center = <200>;
			scale = <1500>;
			scale-div = <1000>;
		};
		aux3 {
			input-type = "velocity";
			input-index = <3>;
			center = <200>;
			scale = <1500>;
			scale-div = <1000>;
		};
	};

	chosen {
		zephyr,canbus = &flexcan3;
	};

	aliases {
		can0 = &flexcan3;
		telem1 = &lpuart5;
		imu-stream-0 = &icm45686;
		accel0 = &icm45686;
		gyro0 = &icm45686;
		mag0 = &ist8310;
		mag1 = &bmm350;
		baro0 = &bmp390;
		power0 = &ina230;
		status-led = &ncp5623c;
		buzzer = &buzzer0;
		rc = &sbus0;
		gnss = &gnss1;
	};
};

&flexcan3 {
	status = "okay";
};

&lpi2c3 {
	ina230: ina230@41 {
		compatible = "ti,ina230";
		reg = <0x41>;
		current-lsb-microamps = <5000>;
		rshunt-micro-ohms = <500>;
	};
};

/* GNSS 1 */
uart0: &lpuart2 {
       status = "okay";
       current-speed = <115200>;

		gnss1: gnss {
				status = "okay";
				compatible = "u-blox,f9p";
				fix-rate = <100>;
		};
};

/* DSHOT */

&pinctrl {
	
	pinmux_dshot_vmu: pinmux_dshot_vmu {
		group0 {
			pinmux = <&iomuxc_gpio_emc_06_flexio1_flexio06>,
				<&iomuxc_gpio_emc_07_flexio1_flexio07>,
				<&iomuxc_gpio_emc_08_flexio1_flexio08>,
				<&iomuxc_gpio_emc_09_flexio1_flexio09>,
				<&iomuxc_gpio_emc_02_flexio1_flexio02>,
				<&iomuxc_gpio_emc_03_flexio1_flexio03>,
				<&iomuxc_gpio_emc_04_flexio1_flexio04>,
				<&iomuxc_gpio_emc_05_flexio1_flexio05>;
			drive-strength = "r0-4";
			bias-pull-up;
			bias-pull-up-value = "47k";
			slew-rate = "fast";
			input-enable;
			nxp,speed = "100-mhz";
		};
	};
};

&flexio1 {
	status = "okay";

	dshot: dshot {
		compatible = "nxp,flexio-dshot";
		pinctrl-0 = <&pinmux_dshot_vmu>;
		pinctrl-names = "default";
		status = "okay";
		speed = <600>;

		ch1 {
			pin-id = <6>;
		};

		ch2 {
			pin-id = <9>;
		};

		ch3 {
			pin-id = <8>;
		};

		ch4 {
			pin-id = <7>;
		};

	};

};
```

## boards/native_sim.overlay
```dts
/*
 * Copyright (c) 2021 Nordic Semiconductor ASA
 * SPDX-License-Identifier: Apache-2.0
 */

/* This devicetree overlay file will be automatically picked by the Zephyr
 * build system when building the sample for the nucleo_f302r8 board. It shows
 * how the example-application can be built on sample boards already provided
 * by Zephyr.
 */

/ {
	chosen {
		zephyr,telem1 = &uart1;
	};
};

/* Required for enabling sdcard logging */
&flash0 {
	reg = <0x00000000 DT_SIZE_K(2048)>;
	partitions {
		compatible = "fixed-partitions";
		#address-cells = <1>;
		#size-cells = <1>;

		flashdisk_partition: partition@0 {
			label = "flashdisk";
			reg = <0x00000000 0x00200000>;
		};
	};
};
/ {
	test_disk: storage_disk {
		compatible = "zephyr,flash-disk";
		partition = <&flashdisk_partition>;
		disk-name = "NAND";
		cache-size = <4096>;
	};
};
```

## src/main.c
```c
/*
 * Copyright (c) 2023 CogniPilot Foundation
 * SPDX-License-Identifier: Apache-2.0
 */

#include <stdio.h>

#include <zephyr/kernel.h>
#include <zephyr/logging/log.h>

#include <cerebri/core/common.h>

LOG_MODULE_REGISTER(rdd2_main, CONFIG_CEREBRI_RDD2_LOG_LEVEL);

int main(void)
{
    LOG_INF("init");
#if defined(CONFIG_CEREBRI_CORE_COMMON_BOOT_BANNER)
    printf("%s%s", banner_brain, banner_name);
#endif
    LOG_INF("Cerebri RDD2 %d.%d.%d", CONFIG_CEREBRI_VERSION_MAJOR, CONFIG_CEREBRI_VERSION_MINOR, CONFIG_CEREBRI_VERSION_PATCH);
    return 0;
}

// vi: ts=4 sw=4 et
```

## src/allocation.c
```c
/*
 * Copyright CogniPilot Foundation 2023
 * SPDX-License-Identifier: Apache-2.0
 */

#include "app/rdd2/casadi/rdd2.h"
#include "math.h"

#include <zephyr/logging/log.h>
#include <zephyr/shell/shell.h>

#include <zros/private/zros_node_struct.h>
#include <zros/private/zros_pub_struct.h>
#include <zros/private/zros_sub_struct.h>
#include <zros/zros_node.h>
#include <zros/zros_pub.h>
#include <zros/zros_sub.h>

#include <synapse_topic_list.h>

#include <cerebri/core/casadi.h>
#include <cerebri/core/log_utils.h>

#define MY_STACK_SIZE 3072
#define MY_PRIORITY   4

#ifndef M_PI
#define M_PI 3.14159265358979323846
#endif

CEREBRI_NODE_LOG_INIT(rdd2_allocation, LOG_LEVEL_WRN);

static K_THREAD_STACK_DEFINE(g_my_stack_area, MY_STACK_SIZE);

struct context {
	struct zros_node node;
	synapse_pb_Status status;
	synapse_pb_Actuators actuators;
	synapse_pb_Vector3 force_sp, moment_sp;
	struct zros_sub sub_status, sub_force_sp, sub_moment_sp;
	struct zros_pub pub_actuators;
	struct k_sem running;
	size_t stack_size;
	k_thread_stack_t *stack_area;
	struct k_thread thread_data;
};

static struct context g_ctx = {
	.node = {},
	.status = synapse_pb_Status_init_default,
	.actuators =
		{
			.has_stamp = true,
			.stamp = synapse_pb_Timestamp_init_default,
			.velocity_count = 4,
			.normalized_count = 0,
			.position_count = 0,
			.position = {},
			.normalized = {},
			.velocity = {},
		},
	.sub_status = {},
	.sub_force_sp = {},
	.sub_moment_sp = {},
	.pub_actuators = {},
	.running = Z_SEM_INITIALIZER(g_ctx.running, 1, 1),
	.stack_size = MY_STACK_SIZE,
	.stack_area = g_my_stack_area,
	.thread_data = {},
};

static void rdd2_allocation_init(struct context *ctx)
{
	zros_node_init(&ctx->node, "rdd2_allocation");
	zros_sub_init(&ctx->sub_status, &ctx->node, &topic_status, &ctx->status, 10);
	zros_sub_init(&ctx->sub_force_sp, &ctx->node, &topic_force_sp, &ctx->force_sp, 1000);
	zros_sub_init(&ctx->sub_moment_sp, &ctx->node, &topic_moment_sp, &ctx->moment_sp, 1000);
	zros_pub_init(&ctx->pub_actuators, &ctx->node, &topic_actuators, &ctx->actuators);
	k_sem_take(&ctx->running, K_FOREVER);
	LOG_INF("init");
}

static void rdd2_allocation_fini(struct context *ctx)
{
	zros_sub_fini(&ctx->sub_status);
	zros_sub_fini(&ctx->sub_force_sp);
	zros_sub_fini(&ctx->sub_moment_sp);
	zros_pub_fini(&ctx->pub_actuators);
	zros_node_fini(&ctx->node);
	k_sem_give(&ctx->running);
	LOG_INF("fini");
}

static void stop(struct context *ctx)
{
	for (int i = 0; i < 4; i++) {
		ctx->actuators.velocity[i] = 0;
	}
}

static void rdd2_allocation_run(void *p0, void *p1, void *p2)
{
	struct context *ctx = p0;
	ARG_UNUSED(p1);
	ARG_UNUSED(p2);

	rdd2_allocation_init(ctx);

	struct k_poll_event events[] = {
		*zros_sub_get_event(&ctx->sub_moment_sp),
	};

	while (k_sem_take(&ctx->running, K_NO_WAIT) < 0) {
		int rc = 0;
		rc = k_poll(events, ARRAY_SIZE(events), K_MSEC(100));
		if (rc != 0) {
			LOG_DBG_RATELIMIT_RATE(30000, "not receiving moment_sp");
		}

		// update subscriptions
		zros_sub_update(&ctx->sub_status);
		zros_sub_update(&ctx->sub_force_sp);
		zros_sub_update(&ctx->sub_moment_sp);

		if (rc < 0) {
			stop(ctx);
			LOG_DBG("no data, stopped");
		} else if (ctx->status.arming != synapse_pb_Status_Arming_ARMING_ARMED) {
			// not armed, stop
			stop(ctx);
		} else {
			static double const F_max = 20.0;
			static double const l = CONFIG_CEREBRI_RDD2_MOTOR_L_MM * 1e-3;
			static double const Cm = CONFIG_CEREBRI_RDD2_MOTOR_CM * 1e-6;
			static double const Ct = CONFIG_CEREBRI_RDD2_MOTOR_CT * 1e-9;
			double omega[4];
			double Fp_sum[4], F_moment[4], F_thrust[4], M_sat[3];
			double moment[3] = {ctx->moment_sp.x, ctx->moment_sp.y, ctx->moment_sp.z};

			// control_allocation:(F_max,l,Cm,Ct,T,M[3])->(omega[4],Fp_sum[4],F_moment[4],F_thrust[4],M_sat[3])
			CASADI_FUNC_ARGS(control_allocation)

			args[0] = &F_max;
			args[1] = &l;
			args[2] = &Cm;
			args[3] = &Ct;
			args[4] = &ctx->force_sp.z;
			args[5] = moment;

			res[0] = omega;
			res[1] = Fp_sum;
			res[2] = F_moment;
			res[3] = F_thrust;
			res[4] = M_sat;
			CASADI_FUNC_CALL(control_allocation)

			for (int i = 0; i < 4; i++) {
				if (!isfinite(omega[i])) {
					LOG_WRN("omega is not finite: %10.4f", omega[i]);
					omega[i] = 0;
				} else if (omega[i] > 3000) {
					LOG_WRN("omega too large: %10.4f", omega[i]);
					omega[i] = 3000;
				} else if (omega[i] < 0) {
					LOG_WRN("omega negative: %10.4f", omega[i]);
					omega[i] = 0;
				}
				ctx->actuators.velocity[i] = omega[i];
			}
		}

		// publish
		stamp_msg(&ctx->actuators.stamp, k_uptime_ticks());
		ctx->actuators.has_stamp = true;
		zros_pub_update(&ctx->pub_actuators);
	}

	rdd2_allocation_fini(ctx);
}

static int start(struct context *ctx)
{
	k_tid_t tid =
		k_thread_create(&ctx->thread_data, ctx->stack_area, ctx->stack_size,
				rdd2_allocation_run, ctx, NULL, NULL, MY_PRIORITY, 0, K_FOREVER);
	k_thread_name_set(tid, "rdd2_allocation");
	k_thread_start(tid);
	return 0;
}

static int rdd2_allocation_cmd_handler(const struct shell *sh, size_t argc, char **argv, void *data)
{
	ARG_UNUSED(argc);
	struct context *ctx = data;

	if (strcmp(argv[0], "start") == 0) {
		if (k_sem_count_get(&g_ctx.running) == 0) {
			shell_print(sh, "already running");
		} else {
			start(ctx);
		}
	} else if (strcmp(argv[0], "stop") == 0) {
		if (k_sem_count_get(&g_ctx.running) == 0) {
			k_sem_give(&g_ctx.running);
		} else {
			shell_print(sh, "not running");
		}
	} else if (strcmp(argv[0], "status") == 0) {
		shell_print(sh, "running: %d", (int)k_sem_count_get(&g_ctx.running) == 0);
	}
	return 0;
}

SHELL_SUBCMD_DICT_SET_CREATE(sub_rdd2_allocation, rdd2_allocation_cmd_handler,
			     (start, &g_ctx, "start"), (stop, &g_ctx, "stop"),
			     (status, &g_ctx, "status"));

SHELL_CMD_REGISTER(rdd2_allocation, &sub_rdd2_allocation, "rdd2 allocation commands", NULL);

static int rdd2_allocation_sys_init(void)
{
	return start(&g_ctx);
};

SYS_INIT(rdd2_allocation_sys_init, APPLICATION, 99);

// vi: ts=4 sw=4 et
```

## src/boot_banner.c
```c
/*
 * Copyright (c) 2023 CogniPilot Foundation
 * SPDX-License-Identifier: Apache-2.0
 */

#include <zephyr/kernel.h>
#include <zephyr/logging/log.h>

#if defined(CONFIG_CEREBRI_CORE_COMMON_BOOT_BANNER)
#include <stdio.h>
#endif

#include <cerebri/core/common.h>
#include <cerebri/core/log_utils.h>

CEREBRI_NODE_LOG_INIT(rdd2_boot_banner, LOG_LEVEL_WRN);

static int rdd2_boot_banner_sys_init(void)
{
	LOG_INF("Cerebri RDD2 %d.%d.%d", CONFIG_CEREBRI_VERSION_MAJOR, CONFIG_CEREBRI_VERSION_MINOR,
		CONFIG_CEREBRI_VERSION_PATCH);
#if defined(CONFIG_CEREBRI_CORE_COMMON_BOOT_BANNER)
	printf("%s%s", banner_brain, banner_name);
#endif
	return 0;
};

SYS_INIT(rdd2_boot_banner_sys_init, APPLICATION, 0);

// vi: ts=4 sw=4 et
```
